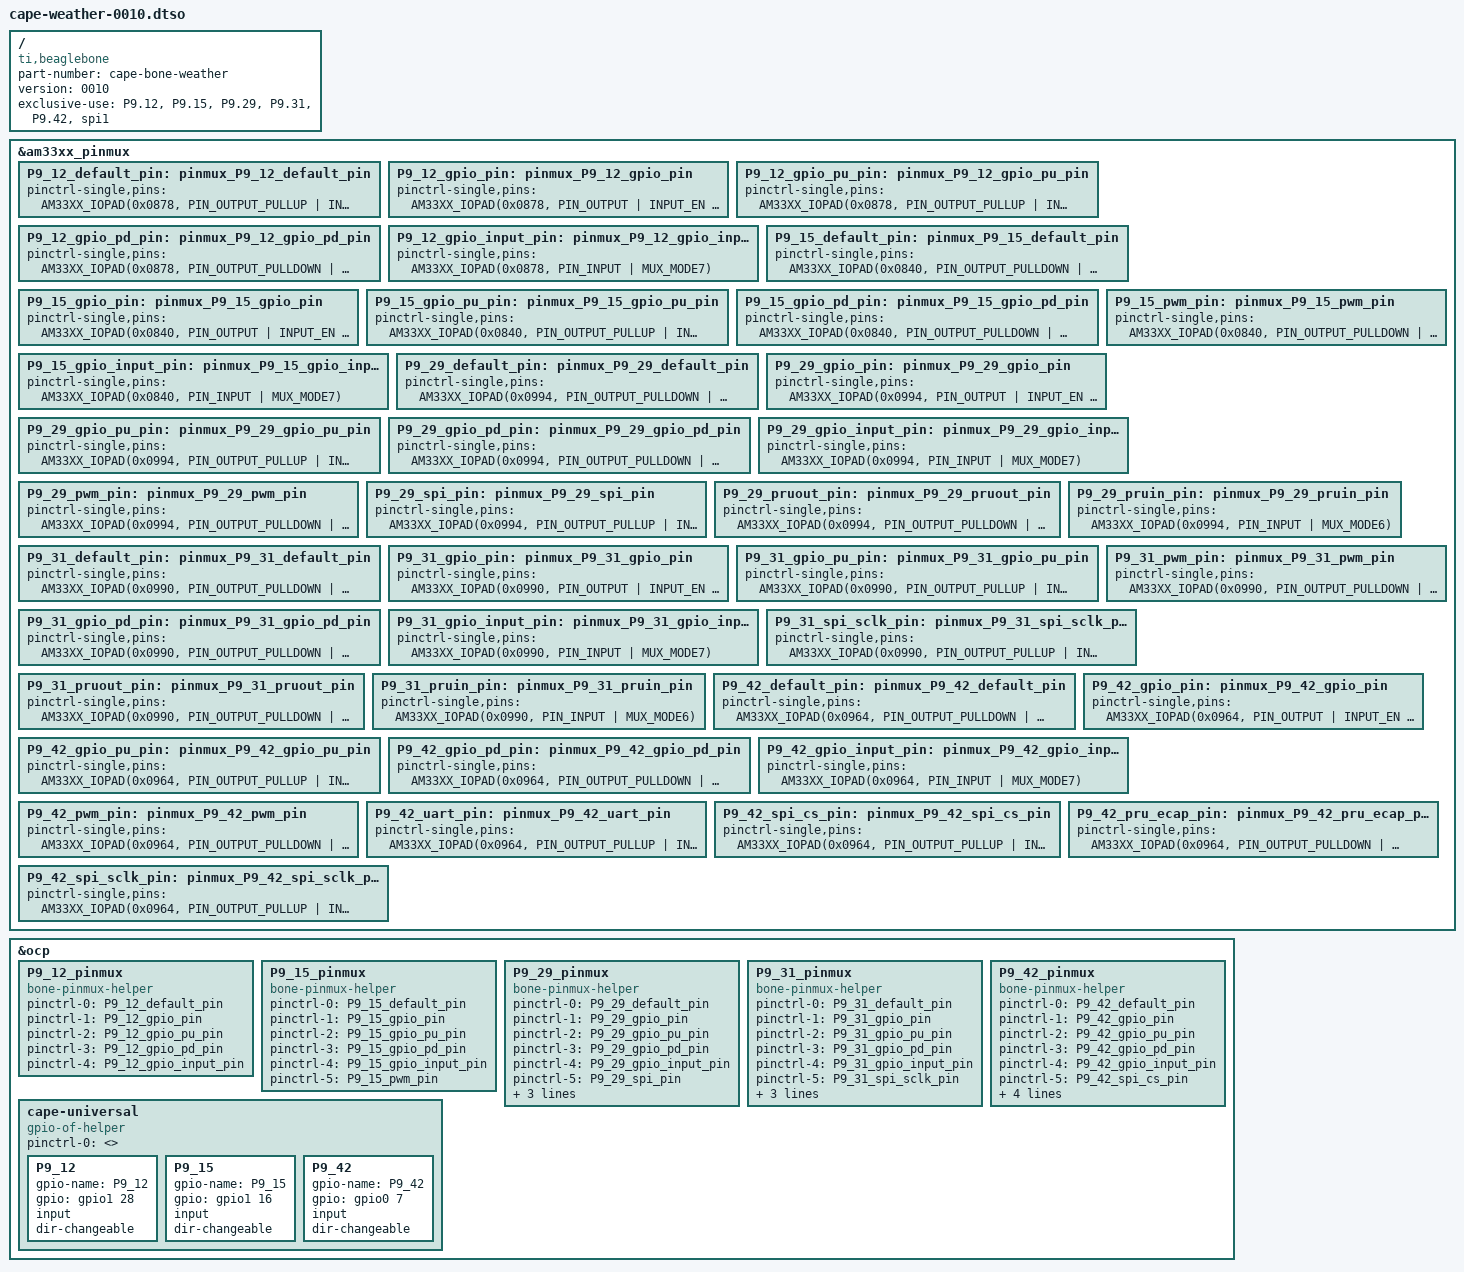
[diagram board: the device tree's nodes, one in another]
#include <dt-bindings/pinctrl/am33xx.h>

/dts-v1/;
/plugin/;

/ {
	compatible = "ti,beaglebone", "ti,beaglebone-black", "ti,beaglebone-green";

	/* identification */
	part-number = "cape-bone-weather";
	version = "0010";

	/* state the resources this cape uses */
	exclusive-use =

		"P9.12",
		"P9.15",
		"P9.29",
		"P9.31",
		"P9.42",
		"spi1";

	fragment@0 {
		target = <&am33xx_pinmux>;
			__overlay__ {

			/************************/
			/* P9 Header */
			/************************/


			/* P9_12 (ZCZ ball U18) gpio1_28 */
			P9_12_default_pin: pinmux_P9_12_default_pin { pinctrl-single,pins = <
				AM33XX_IOPAD(0x0878, PIN_OUTPUT_PULLUP | INPUT_EN | MUX_MODE7) >; };	/* gpmc_be1n.gpio1_28 */
			P9_12_gpio_pin: pinmux_P9_12_gpio_pin { pinctrl-single,pins = <
				AM33XX_IOPAD(0x0878, PIN_OUTPUT | INPUT_EN | MUX_MODE7) >; };		/* gpmc_be1n.gpio1_28 */
			P9_12_gpio_pu_pin: pinmux_P9_12_gpio_pu_pin { pinctrl-single,pins = <
				AM33XX_IOPAD(0x0878, PIN_OUTPUT_PULLUP | INPUT_EN | MUX_MODE7) >; };	/* gpmc_be1n.gpio1_28 */
			P9_12_gpio_pd_pin: pinmux_P9_12_gpio_pd_pin { pinctrl-single,pins = <
				AM33XX_IOPAD(0x0878, PIN_OUTPUT_PULLDOWN | INPUT_EN | MUX_MODE7) >; };	/* gpmc_be1n.gpio1_28 */
			P9_12_gpio_input_pin: pinmux_P9_12_gpio_input_pin { pinctrl-single,pins = <
				AM33XX_IOPAD(0x0878, PIN_INPUT | MUX_MODE7) >; };			/* gpmc_be1n.gpio1_28 */

			/* P9_15 (ZCZ ball R13) gpio1_16 */
			P9_15_default_pin: pinmux_P9_15_default_pin { pinctrl-single,pins = <
				AM33XX_IOPAD(0x0840, PIN_OUTPUT_PULLDOWN | INPUT_EN | MUX_MODE7) >; };	/* gpmc_a0.gpio1_16 */
			P9_15_gpio_pin: pinmux_P9_15_gpio_pin { pinctrl-single,pins = <
				AM33XX_IOPAD(0x0840, PIN_OUTPUT | INPUT_EN | MUX_MODE7) >; };		/* gpmc_a0.gpio1_16 */
			P9_15_gpio_pu_pin: pinmux_P9_15_gpio_pu_pin { pinctrl-single,pins = <
				AM33XX_IOPAD(0x0840, PIN_OUTPUT_PULLUP | INPUT_EN | MUX_MODE7) >; };	/* gpmc_a0.gpio1_16 */
			P9_15_gpio_pd_pin: pinmux_P9_15_gpio_pd_pin { pinctrl-single,pins = <
				AM33XX_IOPAD(0x0840, PIN_OUTPUT_PULLDOWN | INPUT_EN | MUX_MODE7) >; };	/* gpmc_a0.gpio1_16 */
			P9_15_gpio_input_pin: pinmux_P9_15_gpio_input_pin { pinctrl-single,pins = <
				AM33XX_IOPAD(0x0840, PIN_INPUT | MUX_MODE7) >; };			/* gpmc_a0.gpio1_16 */
			P9_15_pwm_pin: pinmux_P9_15_pwm_pin { pinctrl-single,pins = <
				AM33XX_IOPAD(0x0840, PIN_OUTPUT_PULLDOWN | INPUT_EN | MUX_MODE6) >; };	/* gpmc_a0.ehrpwm1_tripzone_input */
			
			/* P9_29 (ZCZ ball B13) audio */
			P9_29_default_pin: pinmux_P9_29_default_pin { pinctrl-single,pins = <
				AM33XX_IOPAD(0x0994, PIN_OUTPUT_PULLDOWN | INPUT_EN | MUX_MODE7) >; };	/* mcasp0_fsx.gpio3_15 */
			P9_29_gpio_pin: pinmux_P9_29_gpio_pin { pinctrl-single,pins = <
				AM33XX_IOPAD(0x0994, PIN_OUTPUT | INPUT_EN | MUX_MODE7) >; };		/* mcasp0_fsx.gpio3_15 */
			P9_29_gpio_pu_pin: pinmux_P9_29_gpio_pu_pin { pinctrl-single,pins = <
				AM33XX_IOPAD(0x0994, PIN_OUTPUT_PULLUP | INPUT_EN | MUX_MODE7) >; };	/* mcasp0_fsx.gpio3_15 */
			P9_29_gpio_pd_pin: pinmux_P9_29_gpio_pd_pin { pinctrl-single,pins = <
				AM33XX_IOPAD(0x0994, PIN_OUTPUT_PULLDOWN | INPUT_EN | MUX_MODE7) >; };	/* mcasp0_fsx.gpio3_15 */
			P9_29_gpio_input_pin: pinmux_P9_29_gpio_input_pin { pinctrl-single,pins = <
				AM33XX_IOPAD(0x0994, PIN_INPUT | MUX_MODE7) >; };			/* mcasp0_fsx.gpio3_15 */
			P9_29_pwm_pin: pinmux_P9_29_pwm_pin { pinctrl-single,pins = <
				AM33XX_IOPAD(0x0994, PIN_OUTPUT_PULLDOWN | INPUT_EN | MUX_MODE1) >; };	/* mcasp0_fsx.ehrpwm0b */
			P9_29_spi_pin: pinmux_P9_29_spi_pin { pinctrl-single,pins = <
				AM33XX_IOPAD(0x0994, PIN_OUTPUT_PULLUP | INPUT_EN | MUX_MODE3) >; };	/* mcasp0_fsx.spi1_d0 */
			P9_29_pruout_pin: pinmux_P9_29_pruout_pin { pinctrl-single,pins = <
				AM33XX_IOPAD(0x0994, PIN_OUTPUT_PULLDOWN | INPUT_EN | MUX_MODE5) >; };	/* mcasp0_fsx.pru0_out1 */
			P9_29_pruin_pin: pinmux_P9_29_pruin_pin { pinctrl-single,pins = <
				AM33XX_IOPAD(0x0994, PIN_INPUT | MUX_MODE6) >; };			/* mcasp0_fsx.pru0_in1 */
			/* P9_31 (ZCZ ball A13) audio */
			P9_31_default_pin: pinmux_P9_31_default_pin { pinctrl-single,pins = <
				AM33XX_IOPAD(0x0990, PIN_OUTPUT_PULLDOWN | INPUT_EN | MUX_MODE7) >; };	/* mcasp0_aclkx.gpio3_14 */
			P9_31_gpio_pin: pinmux_P9_31_gpio_pin { pinctrl-single,pins = <
				AM33XX_IOPAD(0x0990, PIN_OUTPUT | INPUT_EN | MUX_MODE7) >; };		/* mcasp0_aclkx.gpio3_14 */
			P9_31_gpio_pu_pin: pinmux_P9_31_gpio_pu_pin { pinctrl-single,pins = <
				AM33XX_IOPAD(0x0990, PIN_OUTPUT_PULLUP | INPUT_EN | MUX_MODE7) >; };	/* mcasp0_aclkx.gpio3_14 */
			P9_31_gpio_pd_pin: pinmux_P9_31_gpio_pd_pin { pinctrl-single,pins = <
				AM33XX_IOPAD(0x0990, PIN_OUTPUT_PULLDOWN | INPUT_EN | MUX_MODE7) >; };	/* mcasp0_aclkx.gpio3_14 */
			P9_31_gpio_input_pin: pinmux_P9_31_gpio_input_pin { pinctrl-single,pins = <
				AM33XX_IOPAD(0x0990, PIN_INPUT | MUX_MODE7) >; };			/* mcasp0_aclkx.gpio3_14 */
			P9_31_pwm_pin: pinmux_P9_31_pwm_pin { pinctrl-single,pins = <
				AM33XX_IOPAD(0x0990, PIN_OUTPUT_PULLDOWN | INPUT_EN | MUX_MODE1) >; };	/* mcasp0_aclkx.ehrpwm0a */
			P9_31_spi_sclk_pin: pinmux_P9_31_spi_sclk_pin { pinctrl-single,pins = <
				AM33XX_IOPAD(0x0990, PIN_OUTPUT_PULLUP | INPUT_EN | MUX_MODE3) >; };	/* mcasp0_aclkx.spi1_sclk */
			P9_31_pruout_pin: pinmux_P9_31_pruout_pin { pinctrl-single,pins = <
				AM33XX_IOPAD(0x0990, PIN_OUTPUT_PULLDOWN | INPUT_EN | MUX_MODE5) >; };	/* mcasp0_aclkx.pru0_out0 */
			P9_31_pruin_pin: pinmux_P9_31_pruin_pin { pinctrl-single,pins = <
				AM33XX_IOPAD(0x0990, PIN_INPUT | MUX_MODE6) >; };			/* mcasp0_aclkx.pru0_in0 */

			/* P9_42 (ZCZ ball C18) gpio0_7 */
			P9_42_default_pin: pinmux_P9_42_default_pin { pinctrl-single,pins = <
				AM33XX_IOPAD(0x0964, PIN_OUTPUT_PULLDOWN | INPUT_EN | MUX_MODE7) >; };	/* eCAP0_in_PWM0_out.gpio0_7 */
			P9_42_gpio_pin: pinmux_P9_42_gpio_pin { pinctrl-single,pins = <
				AM33XX_IOPAD(0x0964, PIN_OUTPUT | INPUT_EN | MUX_MODE7) >; };		/* eCAP0_in_PWM0_out.gpio0_7 */
			P9_42_gpio_pu_pin: pinmux_P9_42_gpio_pu_pin { pinctrl-single,pins = <
				AM33XX_IOPAD(0x0964, PIN_OUTPUT_PULLUP | INPUT_EN | MUX_MODE7) >; };	/* eCAP0_in_PWM0_out.gpio0_7 */
			P9_42_gpio_pd_pin: pinmux_P9_42_gpio_pd_pin { pinctrl-single,pins = <
				AM33XX_IOPAD(0x0964, PIN_OUTPUT_PULLDOWN | INPUT_EN | MUX_MODE7) >; };	/* eCAP0_in_PWM0_out.gpio0_7 */
			P9_42_gpio_input_pin: pinmux_P9_42_gpio_input_pin { pinctrl-single,pins = <
				AM33XX_IOPAD(0x0964, PIN_INPUT | MUX_MODE7) >; };			/* eCAP0_in_PWM0_out.gpio0_7 */
			P9_42_pwm_pin: pinmux_P9_42_pwm_pin { pinctrl-single,pins = <
				AM33XX_IOPAD(0x0964, PIN_OUTPUT_PULLDOWN | INPUT_EN | MUX_MODE0) >; };	/* eCAP0_in_PWM0_out.ecap0_in_pwm0_out */
			P9_42_uart_pin: pinmux_P9_42_uart_pin { pinctrl-single,pins = <
				AM33XX_IOPAD(0x0964, PIN_OUTPUT_PULLUP | INPUT_EN | MUX_MODE1) >; };	/* eCAP0_in_PWM0_out.uart3_txd */
			P9_42_spi_cs_pin: pinmux_P9_42_spi_cs_pin { pinctrl-single,pins = <
				AM33XX_IOPAD(0x0964, PIN_OUTPUT_PULLUP | INPUT_EN | MUX_MODE2) >; };	/* eCAP0_in_PWM0_out.spi1_cs1 */
			P9_42_pru_ecap_pin: pinmux_P9_42_pru_ecap_pin { pinctrl-single,pins = <
				AM33XX_IOPAD(0x0964, PIN_OUTPUT_PULLDOWN | INPUT_EN | MUX_MODE3) >; };	/* eCAP0_in_PWM0_out.pr1_ecap0_ecap_capin_apwm_o */
			P9_42_spi_sclk_pin: pinmux_P9_42_spi_sclk_pin { pinctrl-single,pins = <
				AM33XX_IOPAD(0x0964, PIN_OUTPUT_PULLUP | INPUT_EN | MUX_MODE4) >; };	/* eCAP0_in_PWM0_out.spi1_sclk */

		};
	};

	/************************/
	/* Pin Multiplexing */
	/************************/

	fragment@1 {
		target = <&ocp>;
		__overlay__ {

			/************************/
			/* P9 Header */
			/************************/

			/* P9_12 (ZCZ ball U18) */
			P9_12_pinmux {
				compatible = "bone-pinmux-helper";
				status = "okay";
				pinctrl-names = "default", "gpio", "gpio_pu", "gpio_pd", "gpio_input";
				pinctrl-0 = <&P9_12_default_pin>;
				pinctrl-1 = <&P9_12_gpio_pin>;
				pinctrl-2 = <&P9_12_gpio_pu_pin>;
				pinctrl-3 = <&P9_12_gpio_pd_pin>;
				pinctrl-4 = <&P9_12_gpio_input_pin>;
			};


			/* P9_15 (ZCZ ball R13) */
			P9_15_pinmux {
				compatible = "bone-pinmux-helper";
				status = "okay";
				pinctrl-names = "default", "gpio", "gpio_pu", "gpio_pd", "gpio_input", "pwm";
				pinctrl-0 = <&P9_15_default_pin>;
				pinctrl-1 = <&P9_15_gpio_pin>;
				pinctrl-2 = <&P9_15_gpio_pu_pin>;
				pinctrl-3 = <&P9_15_gpio_pd_pin>;
				pinctrl-4 = <&P9_15_gpio_input_pin>;
				pinctrl-5 = <&P9_15_pwm_pin>;
			};

			/* P9_29 (ZCZ ball B13) audio */
			P9_29_pinmux {
				compatible = "bone-pinmux-helper";
				status = "okay";
				pinctrl-names = "default", "gpio", "gpio_pu", "gpio_pd", "gpio_input", "spi", "pwm", "pruout", "pruin";
				pinctrl-0 = <&P9_29_default_pin>;
				pinctrl-1 = <&P9_29_gpio_pin>;
				pinctrl-2 = <&P9_29_gpio_pu_pin>;
				pinctrl-3 = <&P9_29_gpio_pd_pin>;
				pinctrl-4 = <&P9_29_gpio_input_pin>;
				pinctrl-5 = <&P9_29_spi_pin>;
				pinctrl-6 = <&P9_29_pwm_pin>;
				pinctrl-7 = <&P9_29_pruout_pin>;
				pinctrl-8 = <&P9_29_pruin_pin>;
			};
			/* P9_31 (ZCZ ball A13) audio */
			P9_31_pinmux {
				compatible = "bone-pinmux-helper";
				status = "okay";
				pinctrl-names = "default", "gpio", "gpio_pu", "gpio_pd", "gpio_input", "spi_sclk", "pwm", "pruout", "pruin";
				pinctrl-0 = <&P9_31_default_pin>;
				pinctrl-1 = <&P9_31_gpio_pin>;
				pinctrl-2 = <&P9_31_gpio_pu_pin>;
				pinctrl-3 = <&P9_31_gpio_pd_pin>;
				pinctrl-4 = <&P9_31_gpio_input_pin>;
				pinctrl-5 = <&P9_31_spi_sclk_pin>;
				pinctrl-6 = <&P9_31_pwm_pin>;
				pinctrl-7 = <&P9_31_pruout_pin>;
				pinctrl-8 = <&P9_31_pruin_pin>;
			};

			/* P9_42 (ZCZ ball C18) */
			P9_42_pinmux {
				compatible = "bone-pinmux-helper";
				status = "okay";
				pinctrl-names = "default", "gpio", "gpio_pu", "gpio_pd", "gpio_input", "spi_cs", "spi_sclk", "uart", "pwm", "pru_ecap";
				pinctrl-0 = <&P9_42_default_pin>;
				pinctrl-1 = <&P9_42_gpio_pin>;
				pinctrl-2 = <&P9_42_gpio_pu_pin>;
				pinctrl-3 = <&P9_42_gpio_pd_pin>;
				pinctrl-4 = <&P9_42_gpio_input_pin>;
				pinctrl-5 = <&P9_42_spi_cs_pin>;
				pinctrl-6 = <&P9_42_spi_sclk_pin>;
				pinctrl-7 = <&P9_42_uart_pin>;
				pinctrl-8 = <&P9_42_pwm_pin>;
				pinctrl-9 = <&P9_42_pru_ecap_pin>;
			};
		};
	};

	fragment@2 {
		target = <&ocp>;
		__overlay__ {
			cape-universal {
				compatible = "gpio-of-helper";
				status = "okay";
				pinctrl-names = "default";
				pinctrl-0 = <>;

				P9_12 {
					gpio-name = "P9_12";
					gpio = <&gpio1 28 0>;
					input;
					dir-changeable;
				};

				P9_15 {
					gpio-name = "P9_15";
					gpio = <&gpio1 16 0>;
					input;
					dir-changeable;
				};

				P9_42 {
					gpio-name = "P9_42";
					gpio = <&gpio0 7 0>;
					input;
					dir-changeable;
				};
			};
		};
	};

	/************************/
	/* I2C / SPI */
	/************************/

/*	fragment@32 {
		target = <&spi1>;
		__overlay__ {
			status = "okay";
			pinctrl-names = "default";
			pinctrl-0 = <>; 

			#address-cells = <1>;
			#size-cells = <0>;

			spi1channel@0 {
				#address-cells = <1>;
				#size-cells = <0>;

				compatible = "spidev";

				reg = <0>;
				spi-max-frequency = <16000000>;
				spi-cpha;
			};
		};
	};*/
};
